# STM32H503xx register map
File version: 1.0
Registers are 32-bit, read-write, reset 0x0 unless marked. A register's access mark holds for its fields unless they carry their own. Offsets are from the block's base; [hi:lo] are bit positions.

## CRS — Clock Recovery System
Base 0x40006000
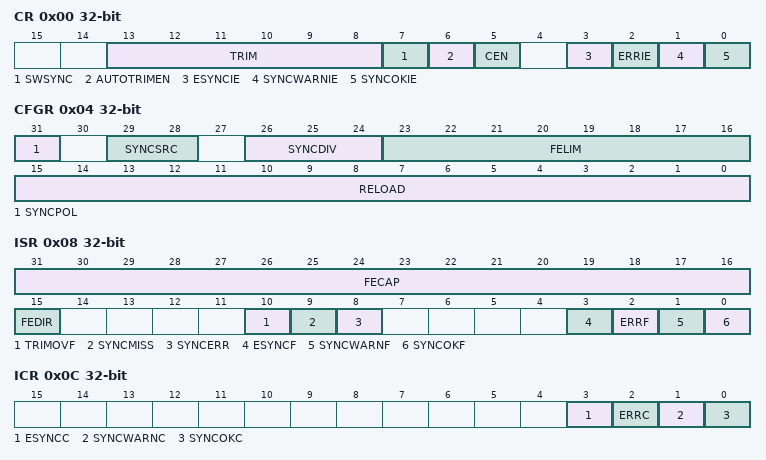
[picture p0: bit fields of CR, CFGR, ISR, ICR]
0x00 CR — CRS ccontrol register
  [13:8] TRIM — HSI48 oscillator smooth trimming
  [7] SWSYNC — Generate software SYNC event
  [6] AUTOTRIMEN — Automatic trimming enable
  [5] CEN — Frequency error counter enable
  [3] ESYNCIE — Expected SYNC interrupt enable
  [2] ERRIE — SYNC error or trimming error interrupt enable
  [1] SYNCWARNIE — SYNC warning interrupt enable
  [0] SYNCOKIE — SYNC event OK interrupt enable
0x04 CFGR — CRS configuration register
  [31] SYNCPOL — SYNC polarity selection
    0=RISING (Synchro Active on rising edge (default)); 1=FALLING (Synchro Active on falling edge)
  [29:28] SYNCSRC — SYNC signal source selection
    0=GPIO (Synchro Signal source GPIO); 1=LSE (Synchro Signal source LSE); 2=USB (Synchro Signal source USB SOF (default))
  [26:24] SYNCDIV — SYNC divider
    0=DIV_1 (Synchro Signal not divided (default)); 1=DIV_2 (Synchro Signal divided by 2); 2=DIV_4 (Synchro Signal divided by 4); 3=DIV_8 (Synchro Signal divided by 8); 4=DIV_16 (Synchro Signal divided by 16); 5=DIV_32 (Synchro Signal divided by 32); 6=DIV_64 (Synchro Signal divided by 64); 7=DIV_128 (Synchro Signal divided by 128)
  [23:16] FELIM — Frequency error limit
  [15:0] RELOAD — Counter reload value
0x08 ISR — CRS interrupt and status register
  [31:16] FECAP — Frequency error capture
  [15] FEDIR — Frequency error direction
    0=UP (Upcounting direction, the actual frequency is above the target); 1=DOWN (Downcounting direction, the actual frequency is below the target)
  [10] TRIMOVF — Trimming overflow or underflow
  [9] SYNCMISS — SYNC missed
  [8] SYNCERR — SYNC error
  [3] ESYNCF — Expected SYNC flag
  [2] ERRF — Error flag
  [1] SYNCWARNF — SYNC warning flag
  [0] SYNCOKF — SYNC event OK flag
0x0C ICR — CRS interrupt flag clear register
  [3] ESYNCC — Expected SYNC clear flag
  [2] ERRC — Error clear flag
  [1] SYNCWARNC — SYNC warning clear flag
  [0] SYNCOKC — SYNC event OK clear flag

## DTS
Base 0x40008C00
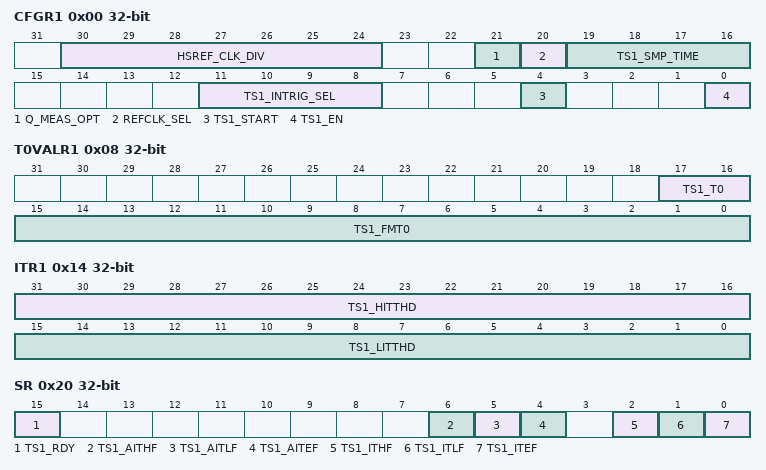
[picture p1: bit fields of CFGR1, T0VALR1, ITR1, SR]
0x00 CFGR1 — DTS configuration register
  [30:24] HSREF_CLK_DIV — High Speed Clock Divider Ratio [6:0]
  [21] Q_MEAS_OPT — Quick measure option bit
  [20] REFCLK_SEL — Reference Clock Selection
  [19:16] TS1_SMP_TIME — Sample time [3:0] for DTS
  [11:8] TS1_INTRIG_SEL — Input triggers selection bits [3:0] for DTS
  [4] TS1_START — Proceed to a frequency measurement on DTS
  [0] TS1_EN — DTS Enable
0x08 T0VALR1 — DTS T0 Value register
  [17:16] TS1_T0 — Engineering value of the DTSerature T0 for DTS
  [15:0] TS1_FMT0 — Engineering value of the measured frequency at T0 for DTS
0x10 RAMPVALR — DTS Ramp value register
  [15:0] TS1_RAMP_COEFF — Engineering value of the ramp coefficient for DTS
0x14 ITR1 — DTS Interrupt threshold register
  [31:16] TS1_HITTHD — High interrupt threshold[15:0] for DTS
  [15:0] TS1_LITTHD — Low interrupt threshold[15:0] for DTS
0x1C DR — DTS data register
  [15:0] TS1_MFREQ — Measured Frequency[15:0] for DTS
0x20 SR — DTS status register
  [15] TS1_RDY — DTS ready flag
  [6] TS1_AITHF — Asynchronous interrupt flag for high threshold for DTS
  [5] TS1_AITLF — Asynchronous interrupt flag for low threshold for DTS
  [4] TS1_AITEF — Asynchronous interrupt flag for end of measure for DTS
  [2] TS1_ITHF — Interrupt flag for high threshold for DTS
  [1] TS1_ITLF — Interrupt flag for low threshold for DTS
  [0] TS1_ITEF — Interrupt flag for end of measure for DTS
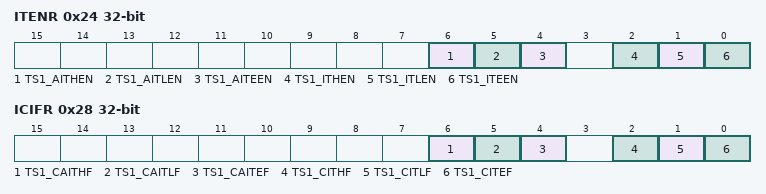
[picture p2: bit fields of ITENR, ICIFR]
0x24 ITENR — DTS Interrupt enable register
  [6] TS1_AITHEN — Enable asynchronous interrupt flag for high threshold for DTS
  [5] TS1_AITLEN — Enable Asynchronous interrupt flag for low threshold for DTS
  [4] TS1_AITEEN — Enable asynchronous interrupt flag for end of measure for DTS
  [2] TS1_ITHEN — Enable interrupt flag for high threshold for DTS
  [1] TS1_ITLEN — Enable interrupt flag for low threshold for DTS
  [0] TS1_ITEEN — Enable interrupt flag for end of measure for DTS
0x28 ICIFR — DTS Clear Interrupt flag register
  [6] TS1_CAITHF — Clear the asynchronous IT flag for high threshold on DTS
  [5] TS1_CAITLF — Clear the asynchronous IT flag for low threshold for DTS
  [4] TS1_CAITEF — Clear the asynchronous IT flag for End Of Measure for DTS
  [2] TS1_CITHF — Clear the IT flag for high threshold on DTS
  [1] TS1_CITLF — Clear the IT flag for low threshold for DTS
  [0] TS1_CITEF — Clear the IT flag for End Of Measure for DTS
0x2C OR — DTS option register 1
